# CY8C5267LTI_LP089 register map
File version: 0.1
Registers are 8-bit, read-write, no defined reset value unless marked. A register's access mark holds for its fields unless they carry their own. Offsets are from the block's base; [hi:lo] are bit positions; 'fields as' and 'values as' point back to an identical list.

## Status_Reg_HwPort
Base 0x00000000
0x4000646A Status_Reg_HwPort_STATUS_REG
0x4000648A Status_Reg_HwPort_MASK_REG
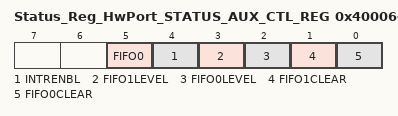
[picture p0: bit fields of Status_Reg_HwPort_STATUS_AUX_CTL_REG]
0x4000649A Status_Reg_HwPort_STATUS_AUX_CTL_REG
  [5] FIFO0 — FIFO0 clear
    1=ENABLED (Enable counter); 0=DISABLED (Disable counter)
  [4] INTRENBL — Enables or disables the Interrupt
    1=ENABLED (Interrupt enabled); 0=DISABLED (Interrupt disabled)
  [3] FIFO1LEVEL — FIFO level
    1=ENABLED (FIFO LVL: input mode: FIFO at least 1/2 empty; output mode: FIFO at least 1/2 full); 0=DISABLED (FIFO LVL: input mode: FIFO not full; output mode: FIFO not empty)
  [2] FIFO0LEVEL — FIFO level
    values as FIFO1LEVEL
  [1] FIFO1CLEAR — FIFO clear
    1=ENABLED (Clear FIFO state); 0=DISABLED (Normal FIFO operation)
  [0] FIFO0CLEAR — FIFO clear
    values as FIFO1CLEAR

## I2C_Master
Base 0x00000000
0x4000640A I2C_Master_DATA — I2C Data Register
  [7:0] data — Read received data or write data to transmit.
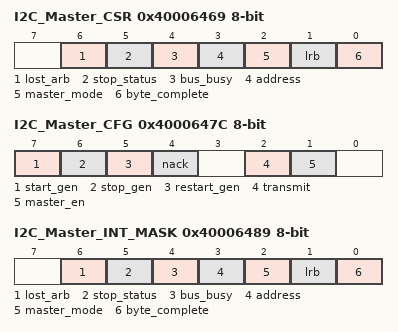
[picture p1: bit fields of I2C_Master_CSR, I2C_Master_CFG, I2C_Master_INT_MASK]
0x40006469 I2C_Master_CSR — I2C Status Register
  [6] lost_arb ro — If set, indicates arbitration was lost (multi-master and multi-master-slave modes).
  [5] stop_status ro — If set, indicates a Stop condition was detected on the bus.
  [4] bus_busy ro — If set, indicates the bus is busy. Data is currently being transmitted or received.
  [3] address ro — Address detection. If set, indicates that an address byte was sent.
  [2] master_mode ro — Indicates that a valid Start condition was generated and a hardware device is operating as bus master.
  [1] lrb ro — Last Received Bit. Indicates the state of the last received bit, which is the ACK/NAK received for the last byte transmitted. Cleared = ACK and set = NAK.
  [0] byte_complete ro — Transmit or receive status since the last read of this register. In Transmit mode this bit indicates that eight bits of data plus ACK/NAK have been transmitted since the last read. In Receive mode this bit indicates that eight bits of data have been received since the last read of this register.
0x4000647C I2C_Master_CFG — I2C Configuration Register
  [7] start_gen — Set to 1 to generate a Start condition on the bus. This bit must be cleared by firmware before initiating the next transaction.
  [6] stop_gen — Set to 1 to generate a Stop condition on the bus. This bit must be cleared by firmware before initiating the next transaction.
  [5] restart_gen — Set to 1 to generate a Restart condition on the bus. This bit must be cleared by firmware after a Restart condition is generated.
  [4] nack — Set to 1 to NAK the next read byte. Clear to ACK next read byte. This bit must be cleared by firmware between bytes.
  [2] transmit — Set to 1 to set the current mode to transmit or clear to 0 to receive a byte of data. This bit must be cleared by firmware before starting the next transmit or receive transaction.
  [1] master_en — Set to 1 to enable the master functionality.
0x40006489 I2C_Master_INT_MASK — I2C Interrupt Enable Mask
  [6] lost_arb — Enables interrupt from the corresponding bit in status register.
  [5] stop_status — Enables interrupt from the corresponding bit in status register.
  [4] bus_busy — Enables interrupt from the corresponding bit in status register.
  [3] address — Enables interrupt from the corresponding bit in status register.
  [2] master_mode — Enables interrupt from the corresponding bit in status register.
  [1] lrb — Enables interrupt from the corresponding bit in status register.
  [0] byte_complete — Enables interrupt from the corresponding bit in status register.

## SleepTimer
Base 0x00000000
0x40004381 SleepTimer_CTW_INTERVAL_REG — Timewheel Configuration Register 1
  [3:0] ctw_interval — Sets the central timewheel interval.
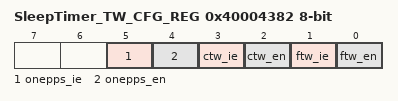
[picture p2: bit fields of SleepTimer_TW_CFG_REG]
0x40004382 SleepTimer_TW_CFG_REG — Timewheel Configuration Register 2
  [5] onepps_ie — When set and one pulse-per-second is enabled, an interrupt is issued when the pulse occurs.
    1=Enabled (One PPS interrupt is enabled); 0=Disabled (One PPS interrupt is disabled)
  [4] onepps_en — When set, the system returns to the active global power mode once every second.
    1=Enabled (One PPS is enabled); 0=Disabled (One PPS is disabled)
  [3] ctw_ie — When set and the central timewheel is enabled, an interrupt is issued when the central timewheel reaches the selected interval.
    1=Enabled (CTW interrupt is enabled); 0=Disabled (CTW interrupt is disabled)
  [2] ctw_en — When set, the system returns to the active global power mode when the central timewheel reaches the selected interval.
    1=Enabled (CTW is enabled); 0=Disabled (CTW is disabled)
  [1] ftw_ie — When set and the fast timewheel is enabled, an interrupt is issued when it reaches the terminal count.
    1=Enabled (FTW interrupt is enabled); 0=Disabled (FTW interrupt is disabled)
  [0] ftw_en — When set, the system returns to the active global power mode when the fast timewheel reaches the selected interval.
    1=Enabled (FTW is enabled); 0=Disabled (FTW is disabled)
